AUTOSAR XML (schema 00048)
package /HuaweiMDC/PlatformApplication/FmApplication/Execution
  executable fm
    root sw component prototype fm: application-type=fm
  executable fm_sea
    root sw component prototype fm: application-type=fm
package /HuaweiMDC/PlatformApplication/FmApplication/SwcComponent
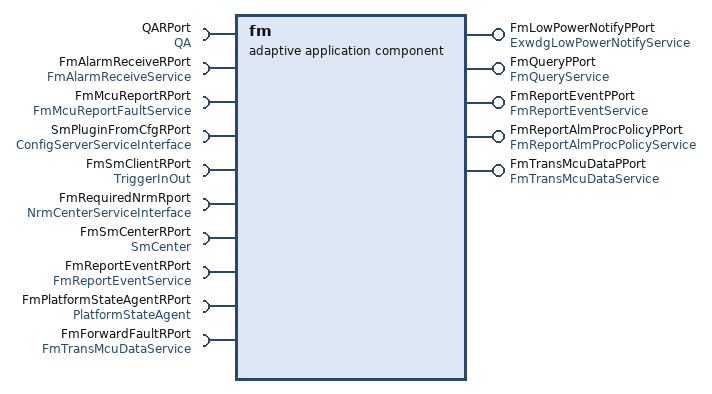
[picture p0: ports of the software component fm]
  adaptive application sw component type fm
    provide port FmLowPowerNotifyPPort: provided-interface=ExwdgLowPowerNotifyService
    provide port FmQueryPPort: provided-interface=FmQueryService
    provide port FmReportEventPPort: provided-interface=FmReportEventService
    5 x require port:
      QARPort: required-interface=QA
      FmAlarmReceiveRPort: required-interface=FmAlarmReceiveService
      FmMcuReportRPort: required-interface=FmMcuReportFaultService
      SmPluginFromCfgRPort: required-interface=ConfigServerServiceInterface
      FmSmClientRPort: required-interface=TriggerInOut
    provide port FmReportAlmProcPolicyPPort: provided-interface=FmReportAlmProcPolicyService
    require port FmRequiredNrmRport: required-interface=NrmCenterServiceInterface
    provide port FmTransMcuDataPPort: provided-interface=FmTransMcuDataService
    4 x require port:
      FmSmCenterRPort: required-interface=SmCenter
      FmReportEventRPort: required-interface=FmReportEventService
      FmPlatformStateAgentRPort: required-interface=PlatformStateAgent
      FmForwardFaultRPort: required-interface=FmTransMcuDataService
  composition sw component type fm_diag
    component fm: type=fm
    component diag_agent: type=diag_agent
